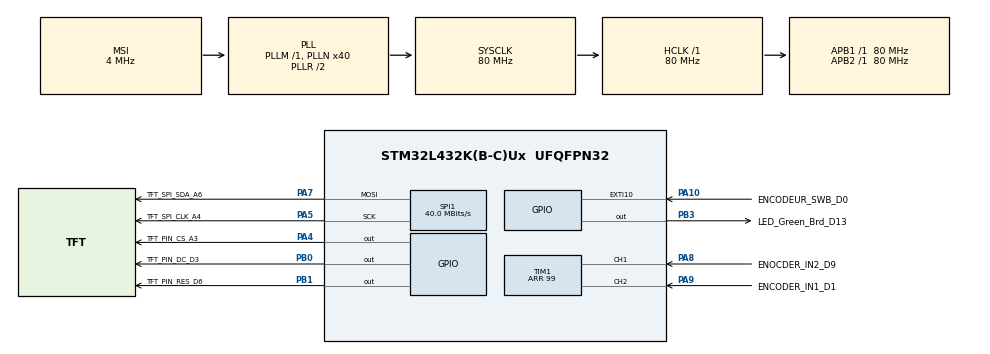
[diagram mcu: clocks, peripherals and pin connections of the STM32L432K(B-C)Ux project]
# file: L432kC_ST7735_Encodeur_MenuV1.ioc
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Mcu.Family=STM32L4
Mcu.Name=STM32L432K(B-C)Ux
Mcu.Package=UFQFPN32
NVIC.EXTI15_10_IRQn=true\:4\:0\:true\:false\:true\:true\:true\:true
NVIC.FLASH_IRQn=true\:0\:0\:false\:false\:true\:true\:true\:true
NVIC.FPU_IRQn=true\:0\:0\:false\:false\:true\:true\:false\:true
NVIC.PVD_PVM_IRQn=true\:0\:0\:false\:false\:true\:true\:true\:true
NVIC.PriorityGroup=NVIC_PRIORITYGROUP_4
NVIC.TIM1_CC_IRQn=true\:0\:0\:false\:false\:true\:true\:true\:true
PA10.GPIO_Label=ENCODEUR_SWB_D0
PA10.GPIO_PuPd=GPIO_PULLUP
PA10.Signal=GPXTI10
PA13\ (JTMS-SWDIO).Mode=Serial_Wire
PA13\ (JTMS-SWDIO).Signal=SYS_JTMS-SWDIO
PA14\ (JTCK-SWCLK).Mode=Serial_Wire
PA14\ (JTCK-SWCLK).Signal=SYS_JTCK-SWCLK
PA4.GPIO_Label=TFT_PIN_CS_A3
PA4.Signal=GPIO_Output
PA5.GPIO_Label=TFT_SPI_CLK_A4
PA5.Mode=TX_Only_Simplex_Unidirect_Master
PA5.Signal=SPI1_SCK
PA7.GPIO_Label=TFT_SPI_SDA_A6
PA7.Mode=TX_Only_Simplex_Unidirect_Master
PA7.Signal=SPI1_MOSI
PA8.GPIO_Label=ENOCDER_IN2_D9
PA8.Signal=S_TIM1_CH1
PA9.GPIO_Label=ENCODER_IN1_D1
PA9.Signal=S_TIM1_CH2
PB0.GPIO_Label=TFT_PIN_DC_D3
PB0.Signal=GPIO_Output
PB1.GPIO_Label=TFT_PIN_RES_D6
PB1.Signal=GPIO_Output
PB3\ (JTDO-TRACESWO).GPIO_Label=LED_Green_Brd_D13
PB3\ (JTDO-TRACESWO).Signal=GPIO_Output
ProjectManager.HeapSize=0x200
ProjectManager.StackSize=0x400
ProjectManager.TargetToolchain=STM32CubeIDE
RCC.ADCFreq_Value=32000000
RCC.AHBFreq_Value=80000000
RCC.APB1Freq_Value=80000000
RCC.APB1TimFreq_Value=80000000
RCC.APB2Freq_Value=80000000
RCC.APB2TimFreq_Value=80000000
RCC.CortexFreq_Value=80000000
RCC.HCLKFreq_Value=80000000
RCC.HSE_VALUE=8000000
RCC.HSI16_VALUE=16000000
RCC.HSI48_VALUE=48000000
RCC.HSI_VALUE=16000000
RCC.LSE_VALUE=32768
RCC.MSI_VALUE=4000000
RCC.PLLMUL=RCC_PLLMUL_4
RCC.PLLN=40
RCC.PLLSAI1N=16
RCC.SYSCLKFreq_VALUE=80000000
RCC.SYSCLKSource=RCC_SYSCLKSOURCE_PLLCLK
RCC.USBFreq_Value=32000000
RCC.VCOOutputFreq_Value=160000000
SH.S_TIM1_CH1.0=TIM1_CH1,Encoder_Interface
SH.S_TIM1_CH2.0=TIM1_CH2,Encoder_Interface
SPI1.BaudRatePrescaler=SPI_BAUDRATEPRESCALER_2
SPI1.CalculateBaudRate=40.0 MBits/s
SPI1.DataSize=SPI_DATASIZE_8BIT
SPI1.Direction=SPI_DIRECTION_2LINES
SPI1.Mode=SPI_MODE_MASTER
SPI1.VirtualType=VM_MASTER
TIM1.IC1Filter=3
TIM1.IC2Filter=3
TIM1.Period=99
board=NUCLEO-L432KC

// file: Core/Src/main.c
/* USER CODE BEGIN Header */
/**
 ******************************************************************************
 * @file           : main.c
 * @brief          : Main program body
 ******************************************************************************
 * @attention
 *
 * Copyright (c) 2024 STMicroelectronics.
 * All rights reserved.
 *
 * This software is licensed under terms that can be found in the LICENSE file
 * in the root directory of this software component.
 * If no LICENSE file comes with this software, it is provided AS-IS.
 *
 ******************************************************************************
 */
/* USER CODE END Header */
#include "main.h"
#include "spi.h"
#include "tim.h"
#include "gpio.h"

/* USER CODE BEGIN Includes */
#include "menu.h"
/* USER CODE END Includes */

/* USER CODE BEGIN PD */
int compteur;
/* USER CODE END PD */

/* USER CODE BEGIN PV */
uint8_t flag=0;
/* USER CODE END PV */

void SystemClock_Config(void);

int main(void)
{

  /* MCU Configuration--------------------------------------------------------*/

  /* Reset of all peripherals, Initializes the Flash interface and the Systick. */
  HAL_Init();

  /* Configure the system clock */
  SystemClock_Config();

  /* Initialize all configured peripherals */
  MX_GPIO_Init();
  MX_SPI1_Init();
  MX_TIM1_Init();

  /* Infinite loop */
  /* USER CODE BEGIN WHILE */
	HAL_TIM_Encoder_Start_IT(&htim1, TIM_CHANNEL_1); // Démarre le mode encodeur
	ST7735_Init();
	menu_demo();
	drawMenu();

	while (1)
	{

    /* USER CODE END WHILE */

	}
}

void SystemClock_Config(void)
{
  RCC_OscInitTypeDef RCC_OscInitStruct = {0};
  RCC_ClkInitTypeDef RCC_ClkInitStruct = {0};

  /** Configure the main internal regulator output voltage
  */
  if (HAL_PWREx_ControlVoltageScaling(PWR_REGULATOR_VOLTAGE_SCALE1) != HAL_OK)
  {
    Error_Handler();
  }

  /** Initializes the RCC Oscillators according to the specified parameters
  * in the RCC_OscInitTypeDef structure.
  */
  RCC_OscInitStruct.OscillatorType = RCC_OSCILLATORTYPE_MSI;
  RCC_OscInitStruct.MSIState = RCC_MSI_ON;
  RCC_OscInitStruct.MSICalibrationValue = 0;
  RCC_OscInitStruct.MSIClockRange = RCC_MSIRANGE_6;
  RCC_OscInitStruct.PLL.PLLState = RCC_PLL_ON;
  RCC_OscInitStruct.PLL.PLLSource = RCC_PLLSOURCE_MSI;
  RCC_OscInitStruct.PLL.PLLM = 1;
  RCC_OscInitStruct.PLL.PLLN = 40;
  RCC_OscInitStruct.PLL.PLLP = RCC_PLLP_DIV7;
  RCC_OscInitStruct.PLL.PLLQ = RCC_PLLQ_DIV2;
  RCC_OscInitStruct.PLL.PLLR = RCC_PLLR_DIV2;
  if (HAL_RCC_OscConfig(&RCC_OscInitStruct) != HAL_OK)
  {
    Error_Handler();
  }

  /** Initializes the CPU, AHB and APB buses clocks
  */
  RCC_ClkInitStruct.ClockType = RCC_CLOCKTYPE_HCLK|RCC_CLOCKTYPE_SYSCLK
                              |RCC_CLOCKTYPE_PCLK1|RCC_CLOCKTYPE_PCLK2;
  RCC_ClkInitStruct.SYSCLKSource = RCC_SYSCLKSOURCE_PLLCLK;
  RCC_ClkInitStruct.AHBCLKDivider = RCC_SYSCLK_DIV1;
  RCC_ClkInitStruct.APB1CLKDivider = RCC_HCLK_DIV1;
  RCC_ClkInitStruct.APB2CLKDivider = RCC_HCLK_DIV1;

  if (HAL_RCC_ClockConfig(&RCC_ClkInitStruct, FLASH_LATENCY_4) != HAL_OK)
  {
    Error_Handler();
  }
}

void Error_Handler(void)
{
	__disable_irq();
	while (1)
	{
	}
}
